# UPD70F3508 register map
Vendor: Renesas; Series: V850E2/Px4; File version: 1.0
CPU: other r0p0, little endian, no MPU, FPU, 4 interrupt priority bits
Registers are 8-bit, read-write, reset 0x0 unless marked. A register's access mark holds for its fields unless they carry their own. Offsets are from the block's base; [hi:lo] are bit positions; lines under a group give offsets from that group.

## BRGA0 — Baud-Rate Generator A0 for CLKOUT pin clock output
Base 0xFF420030
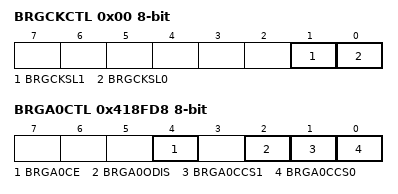
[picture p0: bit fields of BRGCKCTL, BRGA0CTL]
0x00 BRGCKCTL — BRGA0 Clock Selection Register — selects input clock for BRGA0
  [1] BRGCKSL1 — Clock select bit 1 (with BRGCKSL0: 00=SCLK1, 01=PCLK, 10=SCLK2, 11=prohibited)
  [0] BRGCKSL0 — Clock select bit 0
0x418FD8 BRGA0CTL — BRGA0 Control Register — enables counter, sets prescaler, controls CLKOUT output
  [4] BRGA0CE — Baud-rate counter enable: 0=disabled, 1=enabled (INTBRG0 generated)
  [2] BRGA0ODIS — CLKOUT output disable: 0=BRG signal output, 1=fixed low on CLKOUT
  [1] BRGA0CCS1 — Counter clock select bit 1 (with CCS0: 00=BRGATCLK/1, 01=/2, 10=/4, 11=/8)
  [0] BRGA0CCS0 — Counter clock select bit 0
0x418FDC BRGA0CMP — BRGA0 Compare Register — baud-rate counter comparison value [7:0]
  [7:0] BRGA0CMP7_0 — Compare value bits [7:0]; counter match generates INTBRG0 and toggles CLKOUT
0xBDFCD0 BRGA0FLG ro — BRGA0 Flag Register — baud-rate counter operation status (read-only)
  [0] BRGA0CEF — Counter enable flag: 0=stopped, 1=in operation

## DNFSCTL — Digital noise filter sampling clock control register (Table 2-62)
Base 0xFF420034
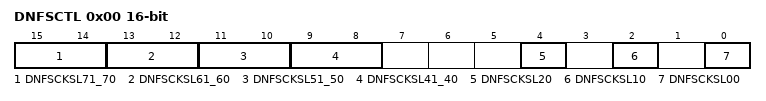
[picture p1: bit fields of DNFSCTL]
0x00 DNFSCTL 16-bit — DNF sampling clock control register
  [15:14] DNFSCKSL71_70 — TAUJ1 group sampling clock: 00=PCLK, 01=PCLK/2, 10=TAUJ1ch0 CKEN
  [13:12] DNFSCKSL61_60 — TAUJ0 group sampling clock: 00=PCLK, 01=PCLK/2, 10=TAUJ0ch0 CKEN
  [11:10] DNFSCKSL51_50 — TAUA1 group sampling clock
  [9:8] DNFSCKSL41_40 — TAUA0 group sampling clock
  [4] DNFSCKSL20 — CSI group sampling clock: 0=PCLK, 1=PCLK/2
  [2] DNFSCKSL10 — TSG2/ENC group sampling clock: 0=PCLK, 1=PCLK/2
  [0] DNFSCKSL00 — INTP group sampling clock: 0=PCLK, 1=PCLK/2

## BIST_CTL — Self-Diagnostic BIST Control Register (µPD70F3505A only, at Reset Controller address space)
Base 0xFF42003C
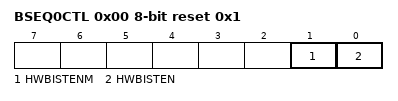
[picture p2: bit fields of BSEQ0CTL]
0x00 BSEQ0CTL reset 0x1 — Self-Diagnostic BIST Control Register — BIST execute/skip selection (µPD70F3505A only; write-protected)
  [1] HWBISTENM — BIST control write status flag — read with HWBISTEN to confirm write state
  [0] HWBISTEN — BIST execution/skip control (0=BIST skipped, 1=BIST executed)

## ECC_CFLASH — Code Flash ECC Error Detection and Address Registers
Base 0xFF432000
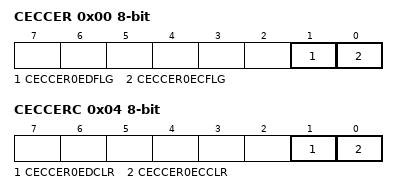
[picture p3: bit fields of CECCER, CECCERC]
0x00 CECCER ro — Code Flash ECC Error Flag Register
  [1] CECCER0EDFLG — ECC uncorrectable error flag (0=no error, 1=uncorrectable error generated)
  [0] CECCER0ECFLG — ECC correction flag (0=no correction, 1=correction occurred)
0x04 CECCERC — Code Flash ECC Error Flag Clear Register — writing 1 clears corresponding CECCER bits
  [1] CECCER0EDCLR — Clear CECCER.CECCER0EDFLG (0=no clear, 1=clear)
  [0] CECCER0ECCLR — Clear CECCER.CECCER0ECFLG (0=no clear, 1=clear)
0x08 CECADR 32-bit ro — Code Flash ECC Error Correction Address Register — holds address where ECC correction was applied
  [21:4] CECADR0A — Address where ECC correction was applied [21:4]
0x0C CEDADR 32-bit ro — Code Flash ECC Error Detection Address Register — holds address where ECC error was detected
  [21:4] CEDADR0A — Address where ECC error was encountered [21:4]

## DFLASH — Data Flash Access Wait Setting Register (Section 3.6)
Base 0xFF436000
0x00 DCLKWAIT reset 0x17 — Data Flash Access Wait Setting Register — sets waiting time for access to data-flash memory
  [4:0] WAIT — Wait cycle setting for data-flash access; valid values: 08H=48MHz, 0AH=64MHz, 0BH=80MHz, 13H=160MHz, 17H=initial

## FLASH_FLMD — FLMD Pin Control Registers (FLMD0 pull-up/pull-down and write protection)
Base 0xFF438000
0x00 FLMDCNT — FLMD Control Register — specifies FLMD0 pin pull-up or pull-down
  [0] FLMDPUP — FLMD0 pin pull direction: 0=pull-down, 1=pull-up
0x04 FLMDPCMD wo — FLMD Protection Command Register — write A5H to begin FLMDCNT write sequence
  [7:0] FLMDPCMD — Protection command byte; write A5H as first step of FLMDCNT write sequence
0x08 FLMDPS ro — FLMD Protection Error Status Register — indicates FLMDCNT write success or failure
  [0] FLMDPRERR — Write protection error: 0=write succeeded, 1=write failed
